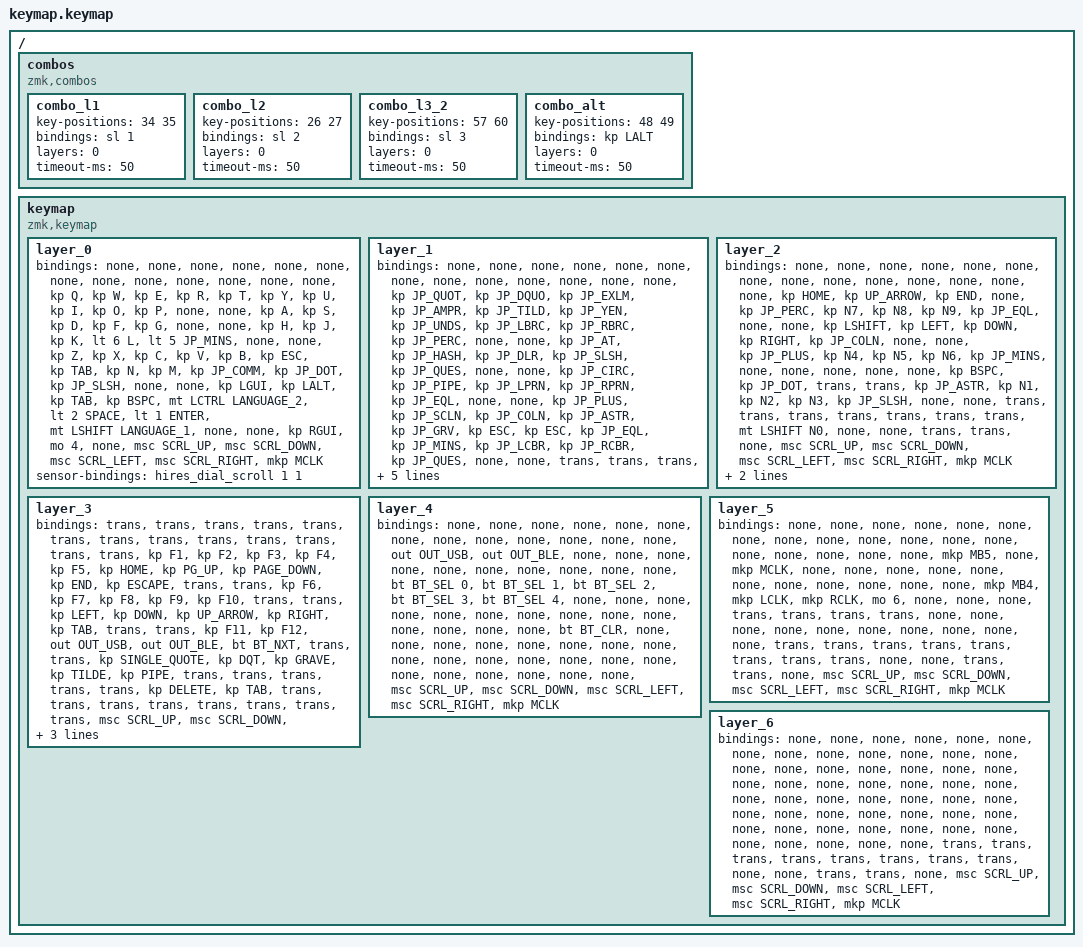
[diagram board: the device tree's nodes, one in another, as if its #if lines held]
#include <behaviors.dtsi>
#include <dt-bindings/zmk/bt.h>
#include <dt-bindings/zmk/keys.h>
#include <dt-bindings/zmk/outputs.h>
#include <dt-bindings/zmk/pointing.h>
#include "jis.h"

#if defined(TORABO_TSUKI_LP_INPUT_HIRES_DIAL)
#include <behaviors/hires_dial.dtsi>
#endif

/ {
    combos {
        compatible = "zmk,combos";

        /*
        bt_clear {
            bindings = <&bt BT_CLR>;
            key-positions = <28 29>;
            layers = <2>;
        };
        */

        // レイヤー1
        combo_l1 {
             key-positions = <34 35>;
                bindings = <&sl 1>;
                layers = <0>;
                timeout-ms = <50>;
        };

        // レイヤー2
        combo_l2 {
             key-positions = <26 27>;
                bindings = <&sl 2>;
                layers = <0>;
                timeout-ms = <50>;
        };

        // レイヤー2
        combo_l3_2 {
             key-positions = <57 60>;
                bindings = <&sl 3>;
                layers = <0>;
                timeout-ms = <50>;
        };

        // alt
        combo_alt {
             key-positions = <48 49>;
                bindings = <&kp LALT>;
                layers = <0>;
                timeout-ms = <50>;
        };
    };

    keymap {
        compatible = "zmk,keymap";

        // デフォルト
        layer_0 {
            bindings = <
&none    &none      &none     &none     &none     &none                                                       &none                  &none    &none        &none       &none          &none
&none    &kp Q      &kp W     &kp E     &kp R     &kp T                                                       &kp Y                  &kp U    &kp I        &kp O       &kp P          &none
&none    &kp A      &kp S     &kp D     &kp F     &kp G                 &none                    &none        &kp H                  &kp J    &kp K        &lt 6 L     &lt 5 JP_MINS  &none
&none    &kp Z      &kp X     &kp C     &kp V     &kp B                 &kp ESC                  &kp TAB      &kp N                  &kp M    &kp JP_COMM  &kp JP_DOT  &kp JP_SLSH    &none
&none    &kp LGUI   &kp LALT  &kp TAB   &kp BSPC  &mt LCTRL LANGUAGE_2  &lt 2 SPACE              &lt 1 ENTER  &mt LSHIFT LANGUAGE_1  &none    &none        &kp RGUI    &mo 4          &none
#if defined(TORABO_TSUKI_LP_KSCAN_4_DIRECTION_SWITCH)
&msc SCRL_UP &msc SCRL_DOWN &msc SCRL_LEFT &msc SCRL_RIGHT &mkp MCLK
#elif defined(TORABO_TSUKI_LP_INPUT_HIRES_DIAL)
&mkp MCLK
#endif
            >;
        };

        // 記号
        layer_1 {
            bindings = <
&none   &none        &none        &none        &none        &none                                &none        &none        &none        &none          &none       &none
&none   &kp JP_QUOT  &kp JP_DQUO  &kp JP_EXLM  &kp JP_AMPR  &kp JP_TILD                          &kp JP_YEN   &kp JP_UNDS  &kp JP_LBRC  &kp JP_RBRC  &kp JP_PERC   &none
&none   &kp JP_AT    &kp JP_HASH  &kp JP_DLR   &kp JP_SLSH  &kp JP_QUES  &none          &none    &kp JP_CIRC  &kp JP_PIPE  &kp JP_LPRN  &kp JP_RPRN  &kp JP_EQL    &none
&none   &kp JP_PLUS  &kp JP_SCLN  &kp JP_COLN  &kp JP_ASTR  &kp JP_GRV   &kp ESC        &kp ESC     &kp JP_EQL   &kp JP_MINS  &kp JP_LCBR  &kp JP_RCBR  &kp JP_QUES   &none
&none   &trans       &trans       &trans       &kp DELETE   &kp LCTRL    &kp LALT       &trans   &trans       &none        &none        &trans       &trans        &none
#if defined(TORABO_TSUKI_LP_KSCAN_4_DIRECTION_SWITCH)
&msc SCRL_UP &msc SCRL_DOWN &msc SCRL_LEFT &msc SCRL_RIGHT &mkp MCLK
#elif defined(TORABO_TSUKI_LP_INPUT_HIRES_DIAL)
&mkp MCLK
#endif
            >;
        };

        // アロー、数字
        layer_2 {
            bindings = <
&none   &none        &none     &none         &none      &none                                &none          &none   &none   &none   &none        &none
&none   &none        &kp HOME  &kp UP_ARROW  &kp END    &none                                &kp JP_PERC    &kp N7  &kp N8  &kp N9  &kp JP_EQL   &none
&none   &kp LSHIFT   &kp LEFT  &kp DOWN      &kp RIGHT  &kp JP_COLN  &none          &none    &kp JP_PLUS    &kp N4  &kp N5  &kp N6  &kp JP_MINS  &none
&none   &none        &none     &none         &kp BSPC   &kp JP_DOT   &trans         &trans   &kp JP_ASTR    &kp N1  &kp N2  &kp N3  &kp JP_SLSH  &none
&none   &trans       &trans    &trans        &trans     &trans       &trans         &trans   &mt LSHIFT N0  &none        &none        &trans       &trans        &none
#if defined(TORABO_TSUKI_LP_KSCAN_4_DIRECTION_SWITCH)
&msc SCRL_UP &msc SCRL_DOWN &msc SCRL_LEFT &msc SCRL_RIGHT &mkp MCLK
#elif defined(TORABO_TSUKI_LP_INPUT_HIRES_DIAL)
&kp C_MUTE
#endif
            >;
        };

        // 
        layer_3 {
            bindings = <
&trans  &trans   &trans   &trans        &trans        &trans                      &trans            &trans     &trans         &trans     &trans      &trans
&trans  &kp F1   &kp F2   &kp F3        &kp F4        &kp F5                      &kp HOME          &kp PG_UP  &kp PAGE_DOWN  &kp END    &kp ESCAPE  &trans
&trans  &kp F6   &kp F7   &kp F8        &kp F9        &kp F10     &trans  &trans  &kp LEFT          &kp DOWN   &kp UP_ARROW   &kp RIGHT  &kp TAB     &trans
&trans  &kp F11  &kp F12  &out OUT_USB  &out OUT_BLE  &bt BT_NXT  &trans  &trans  &kp SINGLE_QUOTE  &kp DQT    &kp GRAVE      &kp TILDE  &kp PIPE    &trans
&trans  &trans   &trans   &trans        &kp DELETE    &kp TAB     &trans  &trans  &trans            &trans     &trans         &trans     &trans      &trans
#if defined(TORABO_TSUKI_LP_KSCAN_4_DIRECTION_SWITCH)
&msc SCRL_UP &msc SCRL_DOWN &msc SCRL_LEFT &msc SCRL_RIGHT &mkp MCLK
#elif defined(TORABO_TSUKI_LP_INPUT_HIRES_DIAL)
&hires_dial_radial_controller_button
#endif
            >;
        };

        // Bluetooth
        layer_4 {
            bindings = <
&none  &none          &none           &none          &none         &none                                 &none  &none  &none  &none  &none  &none 
&none  &out OUT_USB   &out OUT_BLE    &none          &none         &none                                 &none  &none  &none  &none  &none  &none 
&none  &bt BT_SEL 0   &bt BT_SEL 1    &bt BT_SEL 2   &bt BT_SEL 3  &bt BT_SEL 4  &none            &none  &none  &none  &none  &none  &none  &none 
&none  &none          &none           &none          &none         &none         &bt BT_CLR       &none  &none  &none  &none  &none  &none  &none 
&none  &none          &none           &none          &none         &none         &none            &none  &none  &none  &none  &none  &none  &none 
#if defined(TORABO_TSUKI_LP_KSCAN_4_DIRECTION_SWITCH)
&msc SCRL_UP &msc SCRL_DOWN &msc SCRL_LEFT &msc SCRL_RIGHT &mkp MCLK
#elif defined(TORABO_TSUKI_LP_INPUT_HIRES_DIAL)
&hires_dial_radial_controller_button
#endif
            >;
        };

        // マウス
        layer_5 {
            bindings = <
&none  &none   &none   &none   &none  &none                     &none     &none      &none      &none  &none  &none 
&none  &none   &none   &none   &none  &none                     &mkp MB5  &none      &mkp MCLK  &none  &none  &none 
&none  &none   &none   &none   &none  &none  &none       &none  &mkp MB4  &mkp LCLK  &mkp RCLK  &mo 6  &none  &none 
&none  &trans  &trans  &trans  &trans &none  &none       &none  &none     &none      &none      &none  &none  &none 
&none  &trans  &trans  &trans  &trans &trans &trans      &trans &trans &none  &none  &trans &trans  &none
#if defined(TORABO_TSUKI_LP_KSCAN_4_DIRECTION_SWITCH)
&msc SCRL_UP &msc SCRL_DOWN &msc SCRL_LEFT &msc SCRL_RIGHT &mkp MCLK
#elif defined(TORABO_TSUKI_LP_INPUT_HIRES_DIAL)
&hires_dial_radial_controller_button
#endif
            >;
        };

        // スクロール
        layer_6 {
            bindings = <
&none  &none   &none   &none   &none  &none                     &none  &none  &none  &none  &none  &none 
&none  &none   &none   &none   &none  &none                     &none  &none  &none  &none  &none  &none 
&none  &none   &none   &none   &none  &none  &none       &none  &none  &none  &none  &none  &none  &none 
&none  &none   &none   &none   &none  &none  &none       &none  &none  &none  &none  &none  &none  &none 
&none  &trans  &trans  &trans  &trans &trans &trans      &trans &trans &none  &none  &trans &trans  &none
#if defined(TORABO_TSUKI_LP_KSCAN_4_DIRECTION_SWITCH)
&msc SCRL_UP &msc SCRL_DOWN &msc SCRL_LEFT &msc SCRL_RIGHT &mkp MCLK
#elif defined(TORABO_TSUKI_LP_INPUT_HIRES_DIAL)
&hires_dial_radial_controller_button
#endif
            >;
        };
/*
        layer_teplate {
            bindings = <
&none  &none   &none   &none   &none  &none                     &none  &none  &none  &none  &none   &none 
&none  &none   &none   &none   &none  &none                     &none  &none  &none  &none  &none   &none 
&none  &none   &none   &none   &none  &none  &none       &none  &none  &none  &none  &none  &none   &none 
&none  &none   &none   &none   &none  &none  &none       &none  &none  &none  &none  &none  &none   &none 
&none  &trans  &trans  &trans  &trans &trans &trans      &trans &trans &none  &none  &trans &trans  &none
#if defined(TORABO_TSUKI_LP_KSCAN_4_DIRECTION_SWITCH)
&msc SCRL_UP &msc SCRL_DOWN &msc SCRL_LEFT &msc SCRL_RIGHT &mkp MCLK
#elif defined(TORABO_TSUKI_LP_INPUT_HIRES_DIAL)
&hires_dial_radial_controller_button
#endif
            >;
        };
*/
    };
};

#if defined(TORABO_TSUKI_LP_INPUT_HIRES_DIAL)
&{/keymap/layer_0} {
    sensor-bindings = <&hires_dial_scroll 1 1>;
};

&{/keymap/layer_1} {
    sensor-bindings = <&hires_dial_scroll 10 1>;
};

&{/keymap/layer_2} {
    sensor-bindings = <&hires_dial_encoder C_VOL_UP C_VOL_DN>;
};

&{/keymap/layer_3} {
    /* Quarter-speed Radial Controller motion: output/input = 1/4. */
    sensor-bindings = <&hires_dial_radial_controller 4 1>;
};
#endif
